AUTOSAR XML (schema 4-2-2)
package /ARPackage_1
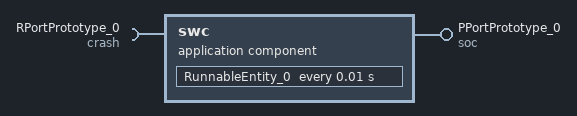
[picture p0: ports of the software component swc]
  application sw component type swc
    provide port PPortPrototype_0: provided-interface=soc
    require port RPortPrototype_0: required-interface=crash
    behavior swc
      timing event TimingEvent_10ms: start-on-event=RunnableEntity_0, period=0.01
      runnable RunnableEntity_0: symbol=RunnableEntity_0_func
        data-read-access:
          access DRA_crash_r_0: accessed-variable=RPortPrototype_0.crash_r
        data-write-access:
          access DWA_soc_p_0: accessed-variable=PPortPrototype_0.soc_p
